VERSION ""

NS_ :

BS_:

BU_:
VAL_TABLE_ pin_diagnostics_state 1 "pdsNOK" 0 "pdsOK" ;

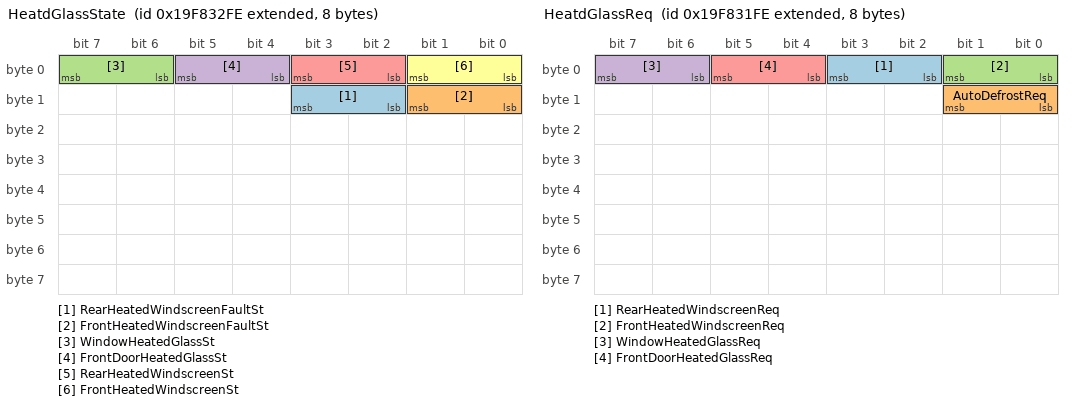
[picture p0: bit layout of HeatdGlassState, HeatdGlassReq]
BO_ 2583180030 HeatdGlassState: 8 Vector__XXX
 SG_ RearHeatedWindscreenFaultSt : 10|2@1+ (1,0) [0|3] "" Vector__XXX
 SG_ FrontHeatedWindscreenFaultSt : 8|2@1+ (1,0) [0|3] "" Vector__XXX
 SG_ WindowHeatedGlassSt : 6|2@1+ (1,0) [0|3] "" Vector__XXX
 SG_ FrontDoorHeatedGlassSt : 4|2@1+ (1,0) [0|3] "" Vector__XXX
 SG_ RearHeatedWindscreenSt : 2|2@1+ (1,0) [0|3] "" Vector__XXX
 SG_ FrontHeatedWindscreenSt : 0|2@1+ (1,0) [0|3] "" Vector__XXX

BO_ 2583179774 HeatdGlassReq: 8 Vector__XXX
 SG_ RearHeatedWindscreenReq : 2|2@1+ (1,0) [0|3] "" Vector__XXX
 SG_ AutoDefrostReq : 8|2@1+ (1,0) [0|3] "" Vector__XXX
 SG_ FrontHeatedWindscreenReq : 0|2@1+ (1,0) [0|3] "" Vector__XXX
 SG_ WindowHeatedGlassReq : 6|2@1+ (1,0) [0|3] "" Vector__XXX
 SG_ FrontDoorHeatedGlassReq : 4|2@1+ (1,0) [0|3] "" Vector__XXX

CM_ "$File: //depot/auto/dbc/Software_Modules/Thermal_System/HGCS/0.3.4.0/HGCS.dbc $
$Change: 215799 $
$DateTime: 2024/08/14 11:25:03 $
$Revision: #1 $";
BA_DEF_ SG_  "SigType" ENUM  "Default","Range","RangeSigned","ASCII","Discrete","Control","ReferencePGN","DTC","StringDelimiter","StringLength","StringLengthControl","MessageCounter","MessageChecksum";
BA_DEF_ SG_  "GenSigEVName" STRING ;
BA_DEF_ SG_  "GenSigILSupport" ENUM  "No","Yes";
BA_DEF_ SG_  "GenSigSendType" ENUM  "Cyclic","OnWrite","OnWriteWithRepetition","OnChange","OnChangeWithRepetition","IfActive","IfActiveWithRepetition","NoSigSendType";
BA_DEF_ SG_  "GenSigStartValue" INT 0 2147483647;
BA_DEF_ BO_  "GenMsgILSupport" ENUM  "No","Yes";
BA_DEF_ BU_  "NmStationAddress" INT 0 255;
BA_DEF_ BO_  "GenMsgSendType" ENUM  "cyclic","NotUsed","IfActive","NotUsed","NotUsed","NotUsed","NotUsed","NotUsed","noMsgSendType";
BA_DEF_ BO_  "GenMsgRequestable" INT 0 1;
BA_DEF_ BO_  "GenMsgCycleTime" INT 0 3600000;
BA_DEF_ BO_  "Producer" STRING ;
BA_DEF_  "DBName" STRING ;
BA_DEF_  "BusType" STRING ;
BA_DEF_  "ProtocolType" STRING ;
BA_DEF_ BO_  "VFrameFormat" ENUM  "StandardCAN","ExtendedCAN","reserved","J1939PG";
BA_DEF_DEF_  "SigType" "Default";
BA_DEF_DEF_  "GenSigEVName" "Env@Nodename_@Signame";
BA_DEF_DEF_  "GenSigILSupport" "Yes";
BA_DEF_DEF_  "GenSigSendType" "NoSigSendType";
BA_DEF_DEF_  "GenSigStartValue" 0;
BA_DEF_DEF_  "GenMsgILSupport" "Yes";
BA_DEF_DEF_  "NmStationAddress" 254;
BA_DEF_DEF_  "GenMsgSendType" "noMsgSendType";
BA_DEF_DEF_  "GenMsgRequestable" 1;
BA_DEF_DEF_  "GenMsgCycleTime" 0;
BA_DEF_DEF_  "Producer" "TMS";
BA_DEF_DEF_  "DBName" "HGCS";
BA_DEF_DEF_  "BusType" "CAN";
BA_DEF_DEF_  "ProtocolType" "J1939";
BA_DEF_DEF_  "VFrameFormat" "J1939PG";
BA_ "GenMsgSendType" BO_ 2583180030 0;
BA_ "GenMsgCycleTime" BO_ 2583180030 1000;
BA_ "Producer" BO_ 2583179774 "HMI";
BA_ "GenMsgSendType" BO_ 2583179774 0;
BA_ "GenMsgCycleTime" BO_ 2583179774 1000;
BA_ "GenSigStartValue" SG_ 2583180030 RearHeatedWindscreenFaultSt 3;
BA_ "GenSigStartValue" SG_ 2583180030 FrontHeatedWindscreenFaultSt 3;
BA_ "GenSigStartValue" SG_ 2583180030 WindowHeatedGlassSt 3;
BA_ "GenSigStartValue" SG_ 2583180030 FrontDoorHeatedGlassSt 3;
BA_ "GenSigStartValue" SG_ 2583180030 RearHeatedWindscreenSt 3;
BA_ "GenSigStartValue" SG_ 2583180030 FrontHeatedWindscreenSt 3;
VAL_ 2583180030 RearHeatedWindscreenFaultSt 3 "NA" 2 "Fault" 1 "NoError" 0 "Error" ;
VAL_ 2583180030 FrontHeatedWindscreenFaultSt 3 "NA" 2 "Fault" 1 "NoError" 0 "Error" ;
VAL_ 2583180030 WindowHeatedGlassSt 3 "Not available" 2 "Error" 1 "On" 0 "Off" ;
VAL_ 2583180030 FrontDoorHeatedGlassSt 3 "Not available" 2 "Error" 1 "On" 0 "Off" ;
VAL_ 2583180030 RearHeatedWindscreenSt 3 "Not available" 2 "Error" 1 "On" 0 "Off" ;
VAL_ 2583180030 FrontHeatedWindscreenSt 3 "Not available" 2 "Error" 1 "On" 0 "Off" ;
VAL_ 2583179774 RearHeatedWindscreenReq 3 "Not available" 2 "Error" 1 "On" 0 "Off" ;
VAL_ 2583179774 AutoDefrostReq 3 "Not available" 2 "Error" 1 "On" 0 "Off" ;
VAL_ 2583179774 FrontHeatedWindscreenReq 3 "Not available" 2 "Error" 1 "On" 0 "Off" ;
VAL_ 2583179774 WindowHeatedGlassReq 3 "Not available" 2 "Error" 1 "On" 0 "Off" ;
VAL_ 2583179774 FrontDoorHeatedGlassReq 3 "Not available" 2 "Error" 1 "On" 0 "Off" ;
